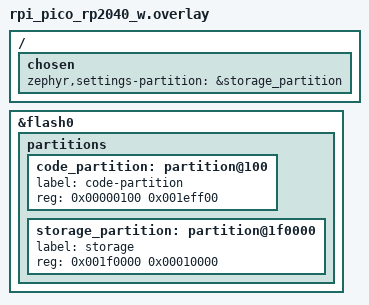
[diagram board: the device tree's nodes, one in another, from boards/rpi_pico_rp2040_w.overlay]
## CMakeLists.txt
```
cmake_minimum_required(VERSION 3.20.0)

# If you want to force the board from here (optional).
# You can also set BOARD in the CLion CMake profile instead.
set(BOARD rpi_pico/rp2040/w CACHE STRING "Zephyr board")

find_package(Zephyr REQUIRED HINTS $ENV{ZEPHYR_BASE})
project(slider)

# App sources
target_sources(app PRIVATE
        src/main.c
        src/wifi_scanner.c
        src/wifi_ap_provisioning.c
        src/http_server.c
        src/wifi_config_gui.c
        src/wifi_shell_commands.c
)

# If you keep headers in src/ (e.g., wifi_creds.h), this is optional because
# Zephyr already adds the app dir include path, but it's harmless and explicit.
target_include_directories(app PRIVATE
        ${CMAKE_CURRENT_SOURCE_DIR}/src
)
```

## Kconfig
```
# This file is the application Kconfig entry point. All application Kconfig
# options can be defined here or included via other application Kconfig files.
# You can browse these options using the west targets menuconfig (terminal) or
# guiconfig (GUI).

menu "Zephyr"
source "Kconfig.zephyr"
endmenu

module = SLIDER
module-str = SLIDER
source "subsys/logging/Kconfig.template.log_config"
```

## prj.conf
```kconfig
# ===============================
# Console + logging + shell
# ===============================
CONFIG_SERIAL=y
CONFIG_CONSOLE=y
CONFIG_UART_CONSOLE=y

CONFIG_LOG=y
CONFIG_LOG_MODE_DEFERRED=y
CONFIG_LOG_DEFAULT_LEVEL=3
CONFIG_LOG_BACKEND_UART=y

# Shell
CONFIG_SHELL=y
CONFIG_SHELL_BACKEND_SERIAL=y
CONFIG_SHELL_PROMPT_UART="slider:~$ "
CONFIG_REBOOT=y

# ===============================
# Flash + partitions
# ===============================
CONFIG_FLASH=y
CONFIG_FLASH_MAP=y

# ===============================
# Settings subsystem (ZMS backend)
# ===============================
CONFIG_SETTINGS=y
CONFIG_SETTINGS_ZMS=y
CONFIG_SETTINGS_RUNTIME=y
CONFIG_ZMS=y
CONFIG_MPU_ALLOW_FLASH_WRITE=y

# ===============================
# Networking + WiFi
# ===============================
CONFIG_NETWORKING=y
CONFIG_NET_IPV4=y
CONFIG_NET_DHCPV4=y
CONFIG_NET_DHCPV4_SERVER=y
CONFIG_NET_MGMT=y
CONFIG_NET_MGMT_EVENT=y

CONFIG_WIFI=y
CONFIG_NET_L2_WIFI_SHELL=y

# Random number generator (required for networking)
CONFIG_ENTROPY_GENERATOR=y
CONFIG_TEST_RANDOM_GENERATOR=y

# Stack sizes for networking and threads
CONFIG_MAIN_STACK_SIZE=8192
CONFIG_NET_TX_STACK_SIZE=4096
CONFIG_NET_RX_STACK_SIZE=4096
CONFIG_SYSTEM_WORKQUEUE_STACK_SIZE=4096

# Additional networking features
CONFIG_NET_SOCKETS=y
CONFIG_POSIX_API=y
CONFIG_NET_TCP=y

# HTTP server requirements
CONFIG_NET_BUF_DATA_SIZE=256
CONFIG_NET_PKT_RX_COUNT=16
CONFIG_NET_PKT_TX_COUNT=16
CONFIG_NET_BUF_RX_COUNT=32
CONFIG_NET_BUF_TX_COUNT=32
CONFIG_NET_MAX_CONTEXTS=10

# Increase heap for dynamic allocations
CONFIG_HEAP_MEM_POOL_SIZE=16384

# Additional shell features
CONFIG_SHELL_STACK_SIZE=4096
CONFIG_SHELL_ARGC_MAX=8
CONFIG_SHELL_CMD_BUFF_SIZE=256
```

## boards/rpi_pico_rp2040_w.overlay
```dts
/ {
	chosen {
		zephyr,settings-partition = &storage_partition;
	};
};

&flash0 {
	partitions {
		/* Shrink code partition to make room for storage */
		code_partition: partition@100 {
			label = "code-partition";
			reg = <0x00000100 0x001eff00>;  /* Code: 256B to 1.937MB */
		};

		/* Storage partition at the end */
		storage_partition: partition@1f0000 {
			label = "storage";
			reg = <0x001f0000 0x00010000>;  /* Storage: last 64KB */
		};
	};
};
```

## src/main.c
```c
/*
 * WiFi Configuration System for Raspberry Pi Pico W
 *
 * Demonstrates comprehensive WiFi management using Zephyr Settings API with ZMS backend.
 *
 * Features:
 * - Boot counter that increments on each reboot
 * - WiFi credential storage (SSID and password)
 * - Automatic WiFi connection on boot if credentials are stored
 * - WiFi network scanning
 * - AP provisioning mode with HTTP configuration interface
 * - GUI framework for display-based configuration
 * - Extended shell commands for management
 * - Persistent storage survives power cycles
 *
 * Shell Commands:
 *   wifi set_ssid <ssid>      - Store WiFi SSID
 *   wifi set_password <pass>  - Store WiFi password
 *   wifi connect              - Connect to WiFi using stored credentials
 *   wifi status               - Show WiFi connection status
 *   wifi_ext reset            - Clear stored WiFi credentials
 *   wifi_ext scan             - Scan for available networks
 *   wifi_ext provision        - Start AP provisioning mode
 *   demo show                 - Display current settings
 *   kernel reboot             - Reboot to test persistence
 */

#include <zephyr/kernel.h>
#include <zephyr/sys/printk.h>
#include <zephyr/settings/settings.h>
#include <zephyr/shell/shell.h>
#include <zephyr/devicetree.h>
#include <zephyr/storage/flash_map.h>
#include <zephyr/device.h>
#include <zephyr/net/net_if.h>
#include <zephyr/net/net_mgmt.h>
#include <zephyr/net/wifi_mgmt.h>
#include <zephyr/net/net_ip.h>
#include <string.h>

/* WiFi configuration modules */
#include "wifi_scanner.h"
#include "wifi_ap_provisioning.h"
#include "http_server.h"
#include "wifi_config_gui.h"
#include "wifi_shell_commands.h"

#define STORAGE_PARTITION_ID FIXED_PARTITION_ID(storage_partition)

/* Settings values */
static uint32_t boot_count = 0;

/* WiFi credentials */
#define WIFI_SSID_MAX 32
#define WIFI_PSK_MAX 64
static char wifi_ssid[WIFI_SSID_MAX + 1] = "";
static char wifi_psk[WIFI_PSK_MAX + 1] = "";
static bool wifi_credentials_set = false;

/* WiFi connection state */
static struct net_mgmt_event_callback wifi_cb;
static bool wifi_connected = false;
static K_SEM_DEFINE(wifi_connected_sem, 0, 1);

/* WiFi configuration system components */
static struct wifi_scanner scanner;
static struct wifi_ap_provisioning ap_prov;
static struct http_server http_srv;
static bool provisioning_mode = false;

/* Forward declarations */
static void provisioning_creds_received(const char *ssid,
                                         const char *password,
                                         void *user_data);
static void start_http_server(void);

/*
 * Settings handler: Set (called when loading from storage)
 */
static int demo_handle_set(const char *name, size_t len,
                           settings_read_cb read_cb, void *cb_arg)
{
    int rc;

    if (strcmp(name, "boot_count") == 0) {
        if (len != sizeof(boot_count)) {
            return -EINVAL;
        }
        rc = read_cb(cb_arg, &boot_count, sizeof(boot_count));
        if (rc >= 0) {
            printk("Loaded boot_count = %u\n", boot_count);
            return 0;
        }
        return rc;
    }

    if (strcmp(name, "wifi_ssid") == 0) {
        if (len > WIFI_SSID_MAX) {
            return -EINVAL;
        }
        rc = read_cb(cb_arg, wifi_ssid, len);
        if (rc >= 0) {
            wifi_ssid[len] = '\0';
            printk("Loaded WiFi SSID = '%s'\n", wifi_ssid);
            return 0;
        }
        return rc;
    }

    if (strcmp(name, "wifi_psk") == 0) {
        if (len > WIFI_PSK_MAX) {
            return -EINVAL;
        }
        rc = read_cb(cb_arg, wifi_psk, len);
        if (rc >= 0) {
            wifi_psk[len] = '\0';
            printk("Loaded WiFi password (***)\n");
            wifi_credentials_set = true;
            return 0;
        }
        return rc;
    }

    return -ENOENT;
}

/*
 * Settings handler: Commit (called after all settings loaded)
 */
static int demo_handle_commit(void)
{
    printk("Settings loaded successfully\n");
    return 0;
}

/*
 * Settings handler: Export (called by settings_save() to enumerate values)
 */
static int demo_handle_export(int (*cb)(const char *name,
                                        const void *value,
                                        size_t val_len))
{
    /* Export with full path including subtree prefix */
    (void)cb("demo/boot_count", &boot_count, sizeof(boot_count));

    if (strlen(wifi_ssid) > 0) {
        (void)cb("demo/wifi_ssid", wifi_ssid, strlen(wifi_ssid));
    }

    if (strlen(wifi_psk) > 0) {
        (void)cb("demo/wifi_psk", wifi_psk, strlen(wifi_psk));
    }

    return 0;
}

/* Register static handler for "demo" subtree */
SETTINGS_STATIC_HANDLER_DEFINE(demo_handler, "demo",
                               NULL,                 /* h_get */
                               demo_handle_set,      /* h_set */
                               demo_handle_commit,   /* h_commit */
                               demo_handle_export);  /* h_export */

/*
 * WiFi event handler
 */
static void wifi_mgmt_event_handler(struct net_mgmt_event_callback *cb,
                                    uint64_t mgmt_event, struct net_if *iface)
{
    const struct wifi_status *status = (const struct wifi_status *)cb->info;

    switch (mgmt_event) {
    case NET_EVENT_WIFI_CONNECT_RESULT:
        if (status->status == 0) {
            wifi_connected = true;
            printk("Connected\n");
        } else {
            printk("Connection failed (status: %d)\n", status->status);
        }
        k_sem_give(&wifi_connected_sem);
        break;
    case NET_EVENT_WIFI_DISCONNECT_RESULT:
        wifi_connected = false;
        printk("Disconnected\n");
        break;
    default:
        break;
    }
}

/*
 * Connect to WiFi using stored credentials
 */
static int wifi_connect_stored(void)
{
    struct net_if *iface = net_if_get_default();
    struct wifi_connect_req_params params = {0};

    if (!iface) {
        printk("ERROR: No network interface found\n");
        return -ENODEV;
    }

    if (strlen(wifi_ssid) == 0) {
        printk("ERROR: No WiFi SSID configured\n");
        return -EINVAL;
    }

    printk("Connecting to WiFi SSID: %s\n", wifi_ssid);

    params.ssid = wifi_ssid;
    params.ssid_length = strlen(wifi_ssid);
    params.psk = wifi_psk;
    params.psk_length = strlen(wifi_psk);
    params.channel = WIFI_CHANNEL_ANY;
    params.security = (strlen(wifi_psk) > 0) ? WIFI_SECURITY_TYPE_PSK : WIFI_SECURITY_TYPE_NONE;
    params.band = WIFI_FREQ_BAND_2_4_GHZ;
    params.mfp = WIFI_MFP_OPTIONAL;

    /* Reset semaphore before connecting */
    k_sem_reset(&wifi_connected_sem);

    /* Send connection request - this is asynchronous */
    net_mgmt(NET_REQUEST_WIFI_CONNECT, iface, &params, sizeof(params));

    /* Wait for connection result event */
    if (k_sem_take(&wifi_connected_sem, K_SECONDS(30)) != 0) {
        printk("Connection timeout\n");
        return -ETIMEDOUT;
    }

    return wifi_connected ? 0 : -ENOEXEC;
}

/*
 * Shell command: set WiFi SSID
 */
static int cmd_wifi_set_ssid(const struct shell *sh, size_t argc, char **argv)
{
    int rc;

    if (argc != 2) {
        shell_error(sh, "Usage: set_ssid <ssid>");
        return -EINVAL;
    }

    if (strlen(argv[1]) > WIFI_SSID_MAX) {
        shell_error(sh, "SSID too long (max %d)", WIFI_SSID_MAX);
        return -EINVAL;
    }

    strncpy(wifi_ssid, argv[1], WIFI_SSID_MAX);
    wifi_ssid[WIFI_SSID_MAX] = '\0';

    rc = settings_save();
    if (rc) {
        shell_error(sh, "Failed to save: %d", rc);
        return rc;
    }

    shell_print(sh, "WiFi SSID saved: '%s'", wifi_ssid);
    return 0;
}

/*
 * Shell command: set WiFi password
 */
static int cmd_wifi_set_password(const struct shell *sh, size_t argc, char **argv)
{
    int rc;

    if (argc != 2) {
        shell_error(sh, "Usage: set_password <password>");
        return -EINVAL;
    }

    if (strlen(argv[1]) > WIFI_PSK_MAX) {
        shell_error(sh, "Password too long (max %d)", WIFI_PSK_MAX);
        return -EINVAL;
    }

    strncpy(wifi_psk, argv[1], WIFI_PSK_MAX);
    wifi_psk[WIFI_PSK_MAX] = '\0';
    wifi_credentials_set = true;

    rc = settings_save();
    if (rc) {
        shell_error(sh, "Failed to save: %d", rc);
        return rc;
    }

    shell_print(sh, "WiFi password saved");
    return 0;
}

/*
 * Start HTTP configuration server
 */
static void start_http_server(void)
{
    int rc;

    /* Check if already running */
    if (http_srv.state == HTTP_SERVER_RUNNING) {
        printk("HTTP server already running\n");
        return;
    }

    /* Wait for DHCP to complete and get IP address */
    printk("Waiting for IP address...\n");
    k_msleep(3000);

    /* Start HTTP server for web configuration interface */
    printk("Starting HTTP configuration server...\n");

    /* Initialize WiFi scanner if not already done */
    if (scanner.state == WIFI_SCANNER_IDLE) {
        rc = wifi_scanner_init(&scanner);
        if (rc) {
            printk("Warning: WiFi scanner init failed: %d\n", rc);
        }
    }

    /* Initialize HTTP server */
    rc = http_server_init(&http_srv, &scanner);
    if (rc == 0) {
        rc = http_server_start(&http_srv, provisioning_creds_received, NULL);
        if (rc == 0) {
            struct net_if *iface = net_if_get_default();
            if (iface && iface->config.ip.ipv4 &&
                iface->config.ip.ipv4->unicast[0].ipv4.addr_state == NET_ADDR_PREFERRED) {
                struct in_addr *addr = &iface->config.ip.ipv4->unicast[0].ipv4.address.in_addr;
                printk("\n");
                printk("===========================================\n");
                printk("  WiFi Configuration Interface Ready\n");
                printk("===========================================\n");
                printk("  Open browser to: http://%d.%d.%d.%d\n",
                       addr->s4_addr[0], addr->s4_addr[1],
                       addr->s4_addr[2], addr->s4_addr[3]);
                printk("===========================================\n\n");
            } else {
                printk("HTTP server started (waiting for IP address)\n");
                printk("Use 'net iface' to check IP address\n");
            }
        } else {
            printk("Warning: Failed to start HTTP server: %d\n", rc);
        }
    } else {
        printk("Warning: Failed to init HTTP server: %d\n", rc);
    }
}

/*
 * Shell command: connect to WiFi
 */
static int cmd_wifi_connect(const struct shell *sh, size_t argc, char **argv)
{
    int rc = wifi_connect_stored();
    if (rc) {
        shell_error(sh, "WiFi connection failed: %d", rc);
        return rc;
    }

    shell_print(sh, "WiFi connected successfully");

    /* Start HTTP server after successful connection */
    start_http_server();

    return 0;
}

/*
 * Shell command: reset WiFi credentials
 */
static int cmd_wifi_reset(const struct shell *sh, size_t argc, char **argv)
{
    int rc;

    shell_print(sh, "Resetting WiFi credentials...");

    /* Clear in-memory variables */
    memset(wifi_ssid, 0, sizeof(wifi_ssid));
    memset(wifi_psk, 0, sizeof(wifi_psk));
    wifi_credentials_set = false;

    /* Delete from persistent storage */
    rc = settings_delete("demo/wifi_ssid");
    if (rc && rc != -ENOENT) {
        shell_error(sh, "Failed to delete SSID: %d", rc);
    }

    rc = settings_delete("demo/wifi_psk");
    if (rc && rc != -ENOENT) {
        shell_error(sh, "Failed to delete password: %d", rc);
    }

    /* Save to persist deletion */
    rc = settings_save();
    if (rc) {
        shell_error(sh, "Failed to save: %d", rc);
        return rc;
    }

    shell_print(sh, "WiFi credentials cleared successfully");
    shell_print(sh, "Device will enter provisioning mode on next boot");
    return 0;
}

/*
 * Shell command: show WiFi status
 */
static int cmd_wifi_status(const struct shell *sh, size_t argc, char **argv)
{
    shell_print(sh, "WiFi Status:");
    shell_print(sh, "  SSID: %s", strlen(wifi_ssid) > 0 ? wifi_ssid : "<not set>");
    shell_print(sh, "  Password: %s", strlen(wifi_psk) > 0 ? "***" : "<not set>");
    shell_print(sh, "  Connected: %s", wifi_connected ? "Yes" : "No");
    return 0;
}

/*
 * Shell command: show all settings
 */
static int cmd_show(const struct shell *sh, size_t argc, char **argv)
{
    shell_print(sh, "Settings:");
    shell_print(sh, "  Boot count: %u", boot_count);
    shell_print(sh, "  WiFi SSID: %s", strlen(wifi_ssid) > 0 ? wifi_ssid : "<not set>");
    shell_print(sh, "  WiFi Password: %s", strlen(wifi_psk) > 0 ? "***" : "<not set>");
    shell_print(sh, "  WiFi Connected: %s", wifi_connected ? "Yes" : "No");
    return 0;
}

/* Register WiFi shell commands */
SHELL_STATIC_SUBCMD_SET_CREATE(wifi_cmds,
    SHELL_CMD(set_ssid, NULL, "Set WiFi SSID", cmd_wifi_set_ssid),
    SHELL_CMD(set_password, NULL, "Set WiFi password", cmd_wifi_set_password),
    SHELL_CMD(connect, NULL, "Connect to WiFi", cmd_wifi_connect),
    SHELL_CMD(reset, NULL, "Clear WiFi credentials", cmd_wifi_reset),
    SHELL_CMD(status, NULL, "Show WiFi status", cmd_wifi_status),
    SHELL_SUBCMD_SET_END
);

SHELL_CMD_REGISTER(wifi, &wifi_cmds, "WiFi commands", NULL);

/* Register demo shell commands */
SHELL_STATIC_SUBCMD_SET_CREATE(demo_cmds,
    SHELL_CMD(show, NULL, "Show all settings", cmd_show),
    SHELL_SUBCMD_SET_END
);

SHELL_CMD_REGISTER(demo, &demo_cmds, "Settings demo commands", NULL);

/*
 * Provisioning credentials callback
 *
 * Called when user submits WiFi credentials via AP provisioning interface
 */
static void provisioning_creds_received(const char *ssid,
                                         const char *password,
                                         void *user_data)
{
	ARG_UNUSED(user_data);

	printk("\n=== New WiFi Credentials Received ===\n");
	printk("SSID: %s\n", ssid);
	printk("Password: ***\n");

	/* Store new credentials */
	if (strlen(ssid) <= WIFI_SSID_MAX) {
		strncpy(wifi_ssid, ssid, WIFI_SSID_MAX);
		wifi_ssid[WIFI_SSID_MAX] = '\0';
	}

	if (strlen(password) <= WIFI_PSK_MAX) {
		strncpy(wifi_psk, password, WIFI_PSK_MAX);
		wifi_psk[WIFI_PSK_MAX] = '\0';
		wifi_credentials_set = true;
	}

	/* Save to flash */
	int rc = settings_save();
	if (rc) {
		printk("Warning: Failed to save credentials: %d\n", rc);
	} else {
		printk("Credentials saved to flash\n");
	}

	/* Stop provisioning mode */
	printk("Stopping provisioning mode...\n");
	http_server_stop(&http_srv);
	wifi_ap_provisioning_stop(&ap_prov);
	provisioning_mode = false;

	/* Wait for AP to fully stop before attempting station mode */
	printk("Waiting for AP to shut down...\n");
	k_msleep(2000);

	/* Try to connect to new network */
	printk("Attempting to connect to new network...\n");
	wifi_connect_stored();
}

/*
 * Start AP provisioning mode
 *
 * Creates an access point and HTTP server for WiFi configuration
 */
static int start_provisioning_mode(void)
{
	int rc;

	if (provisioning_mode) {
		printk("Already in provisioning mode\n");
		return 0;
	}

	printk("\n=== Entering Provisioning Mode ===\n");

	/* Initialize WiFi scanner */
	rc = wifi_scanner_init(&scanner);
	if (rc) {
		printk("ERROR: WiFi scanner init failed: %d\n", rc);
		return rc;
	}

	/* Scan for networks to show in web interface */
	printk("Scanning for WiFi networks...\n");
	rc = wifi_scanner_scan(&scanner, 10000);
	if (rc) {
		printk("Warning: WiFi scan failed: %d\n", rc);
	} else {
		size_t count;
		wifi_scanner_get_results(&scanner, &count);
		printk("Found %zu networks\n", count);
	}

	/* Initialize HTTP server */
	rc = http_server_init(&http_srv, &scanner);
	if (rc) {
		printk("ERROR: HTTP server init failed: %d\n", rc);
		return rc;
	}

	/* Initialize AP provisioning */
	rc = wifi_ap_provisioning_init(&ap_prov, NULL);
	if (rc) {
		printk("ERROR: AP provisioning init failed: %d\n", rc);
		return rc;
	}

	/* Note: AP mode support on Pico W is limited in Zephyr.
	 * For now, provisioning via serial shell is the primary method.
	 * Future: Add BLE provisioning or use external AP hardware.
	 */

	/* Start AP - may not be fully supported on CYW43439 */
	rc = wifi_ap_provisioning_start(&ap_prov, provisioning_creds_received, NULL);
	if (rc) {
		printk("WARNING: AP mode not available: %d\n", rc);
		printk("Use shell commands for WiFi configuration:\n");
		printk("  wifi set_ssid <ssid>\n");
		printk("  wifi set_password <pass>\n");
		printk("  wifi connect\n");
		/* Don't fail - allow shell configuration */
		provisioning_mode = false;
		return 0;
	}

	/* Start HTTP server */
	rc = http_server_start(&http_srv, provisioning_creds_received, NULL);
	if (rc) {
		printk("ERROR: Failed to start HTTP server: %d\n", rc);
		wifi_ap_provisioning_stop(&ap_prov);
		return rc;
	}

	provisioning_mode = true;

	printk("\n");
	printk("===========================================\n");
	printk("  WiFi Provisioning Mode Active\n");
	printk("===========================================\n");
	printk("1. Connect to WiFi network: %s\n", WIFI_AP_DEFAULT_SSID);
	printk("2. Open browser to: http://%s\n", WIFI_AP_DEFAULT_IP);
	printk("3. Select your WiFi network and enter password\n");
	printk("===========================================\n\n");

	return 0;
}

/*
 * Main application
 */
int main(void)
{
    int rc;
    const struct flash_area *fa;
    const struct device *flash_dev;

    printk("\n=== Settings Demo ===\n");
    printk("Board: Raspberry Pi Pico W\n\n");

    /* Verify flash device is ready */
    rc = flash_area_open(STORAGE_PARTITION_ID, &fa);
    if (rc) {
        printk("ERROR: Failed to open storage partition: %d\n", rc);
        return rc;
    }

    flash_dev = fa->fa_dev;
    if (!device_is_ready(flash_dev)) {
        printk("ERROR: Flash device not ready\n");
        flash_area_close(fa);
        return -ENODEV;
    }

    printk("Flash storage ready (offset=0x%lx size=0x%lx)\n",
           (unsigned long)fa->fa_off, (unsigned long)fa->fa_size);
    flash_area_close(fa);

    /* Initialize settings subsystem */
    rc = settings_subsys_init();
    if (rc) {
        printk("ERROR: Settings initialization failed: %d\n", rc);
        return rc;
    }

    /* Load existing settings from flash */
    rc = settings_load();
    if (rc) {
        printk("Warning: Settings load returned %d\n", rc);
    }

    /* Increment and save boot counter */
    boot_count++;
    printk("\nBoot count: %u\n", boot_count);

    rc = settings_save();
    if (rc) {
        printk("Warning: Failed to save boot count: %d\n", rc);
    }

    /* Initialize WiFi management callbacks */
    net_mgmt_init_event_callback(&wifi_cb, wifi_mgmt_event_handler,
                                 NET_EVENT_WIFI_CONNECT_RESULT |
                                 NET_EVENT_WIFI_DISCONNECT_RESULT);
    net_mgmt_add_event_callback(&wifi_cb);

    /* Initialize extended WiFi shell commands */
    wifi_shell_commands_init(&scanner, &ap_prov);

    /* Auto-connect to WiFi if credentials are stored */
    if (strlen(wifi_ssid) > 0 && wifi_credentials_set) {
        printk("\nAuto-connecting to WiFi...\n");

        /* Wait for WiFi subsystem to be fully ready */
        k_msleep(2000);

        rc = wifi_connect_stored();
        if (rc == 0) {
            printk("Auto-connect successful\n");
            start_http_server();
        } else {
            printk("Auto-connect failed (use 'wifi connect' to retry)\n");
        }
    } else {
        printk("\nNo WiFi credentials stored.\n");
        printk("Entering AP provisioning mode...\n");

        /* Start provisioning mode if no credentials */
        rc = start_provisioning_mode();
        if (rc) {
            printk("ERROR: Failed to start provisioning mode: %d\n", rc);
            printk("Use shell commands to configure WiFi manually\n");
        }
    }

    /* Display available commands */
    printk("\nShell commands:\n");
    printk("  wifi set_ssid <ssid>      - Store WiFi SSID\n");
    printk("  wifi set_password <pass>  - Store WiFi password\n");
    printk("  wifi connect              - Connect to WiFi\n");
    printk("  wifi status               - Show WiFi status\n");
    printk("  wifi_ext reset            - Clear WiFi credentials\n");
    printk("  wifi_ext scan             - Scan for networks\n");
    printk("  wifi_ext provision        - Start provisioning mode\n");
    printk("  demo show                 - Show all settings\n");
    printk("  kernel reboot             - Test persistence\n\n");

    /* Main loop */
    while (1) {
        k_sleep(K_SECONDS(10));
    }

    return 0;
}
```

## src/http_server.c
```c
/**
 * @file http_server.c
 * @brief Simple HTTP server implementation for WiFi provisioning
 */

#include "http_server.h"
#include <zephyr/net/socket.h>
#include <zephyr/logging/log.h>
#include <string.h>
#include <stdio.h>

LOG_MODULE_REGISTER(http_server, LOG_LEVEL_INF);

/* HTTP server thread stack */
#define HTTP_SERVER_STACK_SIZE 4096
#define HTTP_SERVER_PRIORITY 5

K_THREAD_STACK_DEFINE(http_server_stack, HTTP_SERVER_STACK_SIZE);

/* HTML template for configuration page */
static const char html_header[] =
	"HTTP/1.1 200 OK\r\n"
	"Content-Type: text/html\r\n"
	"Connection: close\r\n\r\n";

static const char html_page_start[] =
	"<!DOCTYPE html><html><head>"
	"<meta name='viewport' content='width=device-width,initial-scale=1'>"
	"<title>WiFi Setup</title>"
	"<style>"
	"body{font-family:Arial,sans-serif;margin:20px;background:#f0f0f0;}"
	"h1{color:#333;}"
	".container{background:white;padding:20px;border-radius:8px;max-width:600px;margin:0 auto;}"
	".network{padding:10px;margin:5px 0;border:1px solid #ddd;border-radius:4px;cursor:pointer;}"
	".network:hover{background:#e8f4f8;}"
	".signal{float:right;color:#666;}"
	"input[type=text],input[type=password]{width:100%;padding:10px;margin:8px 0;border:1px solid #ddd;border-radius:4px;box-sizing:border-box;}"
	"button{background:#4CAF50;color:white;padding:12px 20px;border:none;border-radius:4px;cursor:pointer;width:100%;font-size:16px;}"
	"button:hover{background:#45a049;}"
	".security{color:#666;font-size:0.9em;}"
	"</style></head><body>"
	"<div class='container'>"
	"<h1>WiFi Configuration</h1>"
	"<p>Select a network or enter credentials manually:</p>";

static const char html_form[] =
	"<form method='POST' action='/connect'>"
	"<label>SSID:</label><input type='text' id='ssid' name='ssid' required>"
	"<label>Password:</label><input type='password' name='password'>"
	"<button type='submit'>Connect</button>"
	"</form>";

static const char html_page_end[] =
	"</div>"
	"<script>"
	"function selectNetwork(ssid){document.getElementById('ssid').value=ssid;}"
	"</script>"
	"</body></html>";

static const char html_success[] =
	"HTTP/1.1 200 OK\r\n"
	"Content-Type: text/html\r\n"
	"Connection: close\r\n\r\n"
	"<!DOCTYPE html><html><head><title>Success</title></head><body>"
	"<h1>WiFi Configuration Saved</h1>"
	"<p>The device will now attempt to connect to the specified network.</p>"
	"<p>This setup page will close shortly.</p>"
	"</body></html>";

/**
 * @brief Parse HTTP POST data for credentials
 *
 * @param data POST data string
 * @param ssid Output buffer for SSID
 * @param password Output buffer for password
 * @return 0 on success, -1 on failure
 */
static int parse_post_data(const char *data, char *ssid, char *password)
{
	const char *ssid_start, *ssid_end;
	const char *pass_start, *pass_end;

	/* Find SSID */
	ssid_start = strstr(data, "ssid=");
	if (!ssid_start) {
		return -1;
	}
	ssid_start += 5;  /* Skip "ssid=" */

	ssid_end = strchr(ssid_start, '&');
	if (!ssid_end) {
		ssid_end = ssid_start + strlen(ssid_start);
	}

	size_t ssid_len = ssid_end - ssid_start;
	if (ssid_len > 32) {
		ssid_len = 32;
	}
	strncpy(ssid, ssid_start, ssid_len);
	ssid[ssid_len] = '\0';

	/* URL decode SSID (replace + with space, handle %XX) */
	for (size_t i = 0; ssid[i]; i++) {
		if (ssid[i] == '+') {
			ssid[i] = ' ';
		}
	}

	/* Find password */
	pass_start = strstr(data, "password=");
	if (pass_start) {
		pass_start += 9;  /* Skip "password=" */
		pass_end = strchr(pass_start, '&');
		if (!pass_end) {
			pass_end = pass_start + strlen(pass_start);
		}

		size_t pass_len = pass_end - pass_start;
		if (pass_len > 64) {
			pass_len = 64;
		}
		strncpy(password, pass_start, pass_len);
		password[pass_len] = '\0';

		/* URL decode password */
		for (size_t i = 0; password[i]; i++) {
			if (password[i] == '+') {
				password[i] = ' ';
			}
		}
	} else {
		password[0] = '\0';
	}

	return 0;
}

/**
 * @brief Handle HTTP client connection
 *
 * @param server HTTP server context
 * @param client_sock Client socket
 */
static void handle_client(struct http_server *server, int client_sock)
{
	char buffer[1024];
	int ret;

	/* Receive HTTP request */
	ret = recv(client_sock, buffer, sizeof(buffer) - 1, 0);
	if (ret <= 0) {
		close(client_sock);
		return;
	}
	buffer[ret] = '\0';

	LOG_DBG("HTTP request received: %d bytes", ret);

	/* Check if POST request with credentials */
	if (strncmp(buffer, "POST /connect", 13) == 0) {
		char ssid[33] = {0};
		char password[65] = {0};

		/* Find POST data (after \r\n\r\n) */
		const char *post_data = strstr(buffer, "\r\n\r\n");
		if (post_data && parse_post_data(post_data + 4, ssid, password) == 0) {
			LOG_INF("Credentials received: SSID=%s", ssid);

			/* Send success response */
			send(client_sock, html_success, strlen(html_success), 0);

			/* Call credentials callback */
			if (server->creds_cb) {
				server->creds_cb(ssid, password, server->cb_user_data);
			}
		}
	} else {
		/* Send configuration page */
		send(client_sock, html_header, strlen(html_header), 0);
		send(client_sock, html_page_start, strlen(html_page_start), 0);

		/* Add scan results if available */
		if (server->scanner) {
			size_t count;
			const struct wifi_scan_result *results =
				wifi_scanner_get_results(server->scanner, &count);

			if (results && count > 0) {
				char network_html[256];

				send(client_sock, "<h2>Available Networks:</h2>", 28, 0);

				for (size_t i = 0; i < count; i++) {
					int signal_bars = (results[i].rssi + 100) / 15;
					if (signal_bars < 0) signal_bars = 0;
					if (signal_bars > 4) signal_bars = 4;

					snprintf(network_html, sizeof(network_html),
					         "<div class='network' onclick='selectNetwork(\"%s\")'>"
					         "%s <span class='signal'>Signal: %d dBm</span><br>"
					         "<span class='security'>%s</span></div>",
					         results[i].ssid, results[i].ssid, results[i].rssi,
					         wifi_scanner_security_to_string(results[i].security));

					send(client_sock, network_html, strlen(network_html), 0);
				}
			}
		}

		/* Send form and end of page */
		send(client_sock, "<h2>Enter Credentials:</h2>", 28, 0);
		send(client_sock, html_form, strlen(html_form), 0);
		send(client_sock, html_page_end, strlen(html_page_end), 0);
	}

	close(client_sock);
}

/**
 * @brief HTTP server thread function
 *
 * @param arg1 Pointer to http_server context
 * @param arg2 Unused
 * @param arg3 Unused
 */
static void http_server_thread(void *arg1, void *arg2, void *arg3)
{
	struct http_server *server = (struct http_server *)arg1;
	struct sockaddr_in addr;
	int ret;

	ARG_UNUSED(arg2);
	ARG_UNUSED(arg3);

	LOG_INF("HTTP server thread started");

	/* Create listening socket */
	server->listen_sock = socket(AF_INET, SOCK_STREAM, IPPROTO_TCP);
	if (server->listen_sock < 0) {
		LOG_ERR("Failed to create socket: %d", errno);
		printk("ERROR: HTTP server failed to create socket: %d\n", errno);
		server->state = HTTP_SERVER_FAILED;
		return;
	}
	printk("HTTP server: socket created (fd=%d)\n", server->listen_sock);

	/* Bind to port */
	addr.sin_family = AF_INET;
	addr.sin_port = htons(HTTP_SERVER_PORT);
	addr.sin_addr.s_addr = INADDR_ANY;

	ret = bind(server->listen_sock, (struct sockaddr *)&addr, sizeof(addr));
	if (ret < 0) {
		LOG_ERR("Failed to bind socket: %d", errno);
		printk("ERROR: HTTP server failed to bind to port %d: %d\n", HTTP_SERVER_PORT, errno);
		close(server->listen_sock);
		server->state = HTTP_SERVER_FAILED;
		return;
	}
	printk("HTTP server: bound to port %d\n", HTTP_SERVER_PORT);

	/* Listen for connections */
	ret = listen(server->listen_sock, HTTP_SERVER_MAX_CONNECTIONS);
	if (ret < 0) {
		LOG_ERR("Failed to listen: %d", errno);
		printk("ERROR: HTTP server failed to listen: %d\n", errno);
		close(server->listen_sock);
		server->state = HTTP_SERVER_FAILED;
		return;
	}

	server->state = HTTP_SERVER_RUNNING;
	LOG_INF("HTTP server listening on port %d", HTTP_SERVER_PORT);
	printk("HTTP server: listening on port %d (ready for connections)\n", HTTP_SERVER_PORT);

	/* Accept and handle connections */
	while (server->running) {
		struct sockaddr_in client_addr;
		socklen_t client_addr_len = sizeof(client_addr);

		int client_sock = accept(server->listen_sock,
		                          (struct sockaddr *)&client_addr,
		                          &client_addr_len);

		if (client_sock < 0) {
			if (server->running) {
				LOG_ERR("Accept failed: %d", errno);
				printk("HTTP server: accept failed: %d\n", errno);
			}
			break;
		}

		LOG_DBG("Client connected");
		printk("HTTP server: client connected from %d.%d.%d.%d\n",
		       ((uint8_t *)&client_addr.sin_addr.s_addr)[0],
		       ((uint8_t *)&client_addr.sin_addr.s_addr)[1],
		       ((uint8_t *)&client_addr.sin_addr.s_addr)[2],
		       ((uint8_t *)&client_addr.sin_addr.s_addr)[3]);
		handle_client(server, client_sock);
	}

	close(server->listen_sock);
	server->state = HTTP_SERVER_STOPPED;
	LOG_INF("HTTP server thread stopped");
}

int http_server_init(struct http_server *server, struct wifi_scanner *scanner)
{
	if (!server) {
		return -EINVAL;
	}

	memset(server, 0, sizeof(struct http_server));
	server->state = HTTP_SERVER_STOPPED;
	server->scanner = scanner;

	LOG_INF("HTTP server initialized");
	return 0;
}

int http_server_start(struct http_server *server,
                       http_server_creds_cb_t creds_cb,
                       void *user_data)
{
	if (!server) {
		return -EINVAL;
	}

	if (server->state == HTTP_SERVER_RUNNING) {
		LOG_WRN("HTTP server already running");
		return -EALREADY;
	}

	server->creds_cb = creds_cb;
	server->cb_user_data = user_data;
	server->running = true;
	server->state = HTTP_SERVER_STARTING;

	/* Create server thread */
	server->server_tid = k_thread_create(
		&server->server_thread,
		http_server_stack,
		HTTP_SERVER_STACK_SIZE,
		http_server_thread,
		server, NULL, NULL,
		HTTP_SERVER_PRIORITY,
		0, K_NO_WAIT);

	if (!server->server_tid) {
		LOG_ERR("Failed to create server thread");
		server->state = HTTP_SERVER_FAILED;
		return -ENOMEM;
	}

	k_thread_name_set(&server->server_thread, "http_server");

	LOG_INF("HTTP server starting...");
	return 0;
}

int http_server_stop(struct http_server *server)
{
	if (!server) {
		return -EINVAL;
	}

	if (server->state != HTTP_SERVER_RUNNING) {
		return -EALREADY;
	}

	LOG_INF("Stopping HTTP server...");

	server->running = false;

	/* Close socket to unblock accept() */
	if (server->listen_sock >= 0) {
		close(server->listen_sock);
	}

	/* Wait for thread to finish */
	k_thread_join(&server->server_thread, K_SECONDS(5));

	return 0;
}

enum http_server_state http_server_get_state(struct http_server *server)
{
	if (!server) {
		return HTTP_SERVER_STOPPED;
	}

	return server->state;
}
```

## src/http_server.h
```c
/**
 * @file http_server.h
 * @brief Simple HTTP server for WiFi provisioning
 *
 * This module provides a lightweight HTTP server that serves a
 * web-based configuration interface for WiFi credential setup.
 */

#pragma once

#include <zephyr/kernel.h>
#include "wifi_scanner.h"

#ifdef __cplusplus
extern "C" {
#endif

/** HTTP server port */
#define HTTP_SERVER_PORT 80

/** Maximum number of concurrent connections */
#define HTTP_SERVER_MAX_CONNECTIONS 2

/**
 * @brief HTTP server state
 */
enum http_server_state {
	HTTP_SERVER_STOPPED,    /**< Server not running */
	HTTP_SERVER_STARTING,   /**< Server starting */
	HTTP_SERVER_RUNNING,    /**< Server running */
	HTTP_SERVER_FAILED      /**< Server failed */
};

/**
 * @brief Credentials submission callback
 *
 * Called when user submits WiFi credentials via web interface
 *
 * @param ssid Selected WiFi SSID
 * @param password WiFi password
 * @param user_data User data pointer
 */
typedef void (*http_server_creds_cb_t)(const char *ssid,
                                        const char *password,
                                        void *user_data);

/**
 * @brief HTTP server context
 */
struct http_server {
	enum http_server_state state;
	int listen_sock;
	struct k_thread server_thread;
	k_tid_t server_tid;
	http_server_creds_cb_t creds_cb;
	void *cb_user_data;
	struct wifi_scanner *scanner;  /**< Reference to WiFi scanner */
	bool running;
};

/**
 * @brief Initialize the HTTP server
 *
 * @param server Pointer to HTTP server context
 * @param scanner Pointer to WiFi scanner (for network list)
 * @return 0 on success, negative errno on failure
 */
int http_server_init(struct http_server *server, struct wifi_scanner *scanner);

/**
 * @brief Start the HTTP server
 *
 * Starts listening for HTTP connections and serves the configuration interface
 *
 * @param server Pointer to HTTP server context
 * @param creds_cb Callback for credential submissions
 * @param user_data User data passed to callback
 * @return 0 on success, negative errno on failure
 */
int http_server_start(struct http_server *server,
                       http_server_creds_cb_t creds_cb,
                       void *user_data);

/**
 * @brief Stop the HTTP server
 *
 * @param server Pointer to HTTP server context
 * @return 0 on success, negative errno on failure
 */
int http_server_stop(struct http_server *server);

/**
 * @brief Get server state
 *
 * @param server Pointer to HTTP server context
 * @return Current server state
 */
enum http_server_state http_server_get_state(struct http_server *server);

#ifdef __cplusplus
}
#endif
```

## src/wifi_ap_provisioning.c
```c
/**
 * @file wifi_ap_provisioning.c
 * @brief WiFi Access Point provisioning implementation
 */

#include "wifi_ap_provisioning.h"
#include <zephyr/net/net_if.h>
#include <zephyr/net/net_mgmt.h>
#include <zephyr/net/wifi_mgmt.h>
#include <zephyr/net/net_ip.h>
#include <zephyr/net/dhcpv4_server.h>
#include <zephyr/logging/log.h>
#include <string.h>
#include <arpa/inet.h>

LOG_MODULE_REGISTER(wifi_ap, LOG_LEVEL_INF);

/* Static instance for callback access */
static struct wifi_ap_provisioning *g_ap_instance = NULL;
static wifi_ap_creds_received_cb_t g_creds_callback = NULL;
static void *g_callback_user_data = NULL;

/**
 * @brief WiFi AP event handler
 *
 * Handles AP enable/disable events
 */
static void wifi_ap_event_handler(struct net_mgmt_event_callback *cb,
                                   uint64_t mgmt_event,
                                   struct net_if *iface)
{
	struct wifi_ap_provisioning *ap = g_ap_instance;

	if (!ap) {
		return;
	}

	switch (mgmt_event) {
	case NET_EVENT_WIFI_AP_ENABLE_RESULT:
	{
		const struct wifi_status *status = (const struct wifi_status *)cb->info;
		if (status && status->status == 0) {
			ap->state = WIFI_AP_ACTIVE;
			LOG_INF("WiFi AP enabled successfully");
		} else {
			ap->state = WIFI_AP_FAILED;
			LOG_ERR("WiFi AP enable failed: %d", status ? status->status : -1);
		}
		break;
	}
	case NET_EVENT_WIFI_AP_DISABLE_RESULT:
	{
		ap->state = WIFI_AP_IDLE;
		LOG_INF("WiFi AP disabled");
		break;
	}
	default:
		break;
	}
}

int wifi_ap_provisioning_init(struct wifi_ap_provisioning *ap,
                               const struct wifi_ap_config *config)
{
	if (!ap) {
		return -EINVAL;
	}

	/* Initialize context */
	memset(ap, 0, sizeof(struct wifi_ap_provisioning));
	ap->state = WIFI_AP_IDLE;

	/* Set configuration (use defaults if not provided) */
	if (config) {
		memcpy(&ap->config, config, sizeof(struct wifi_ap_config));
	} else {
		/* Use default configuration */
		strncpy(ap->config.ssid, WIFI_AP_DEFAULT_SSID, sizeof(ap->config.ssid) - 1);
		strncpy(ap->config.password, WIFI_AP_DEFAULT_PASSWORD, sizeof(ap->config.password) - 1);
		ap->config.channel = WIFI_AP_DEFAULT_CHANNEL;
		strncpy(ap->config.ip_addr, WIFI_AP_DEFAULT_IP, sizeof(ap->config.ip_addr) - 1);
	}

	/* Store global instance for callbacks */
	g_ap_instance = ap;

	/* Register AP event callbacks */
	net_mgmt_init_event_callback(&ap->ap_cb,
	                             wifi_ap_event_handler,
	                             NET_EVENT_WIFI_AP_ENABLE_RESULT |
	                             NET_EVENT_WIFI_AP_DISABLE_RESULT);
	net_mgmt_add_event_callback(&ap->ap_cb);

	LOG_INF("WiFi AP provisioning initialized (SSID: %s)", ap->config.ssid);
	return 0;
}

int wifi_ap_provisioning_start(struct wifi_ap_provisioning *ap,
                                wifi_ap_creds_received_cb_t creds_cb,
                                void *user_data)
{
	struct net_if *iface;
	struct wifi_connect_req_params ap_params = {0};
	int ret;

	if (!ap) {
		return -EINVAL;
	}

	if (ap->state == WIFI_AP_ACTIVE || ap->state == WIFI_AP_STARTING) {
		LOG_WRN("AP already active or starting");
		return -EALREADY;
	}

	/* Store callback */
	g_creds_callback = creds_cb;
	g_callback_user_data = user_data;

	/* Get network interface */
	iface = net_if_get_default();
	if (!iface) {
		LOG_ERR("No default network interface");
		return -ENODEV;
	}

	/* Configure AP parameters */
	ap_params.ssid = ap->config.ssid;
	ap_params.ssid_length = strlen(ap->config.ssid);
	ap_params.channel = ap->config.channel;
	ap_params.band = WIFI_FREQ_BAND_2_4_GHZ;

	/* Set security based on password */
	if (strlen(ap->config.password) > 0) {
		ap_params.security = WIFI_SECURITY_TYPE_PSK;
		ap_params.psk = ap->config.password;
		ap_params.psk_length = strlen(ap->config.password);
	} else {
		ap_params.security = WIFI_SECURITY_TYPE_NONE;
	}

	ap->state = WIFI_AP_STARTING;

	LOG_INF("Starting WiFi AP (SSID: %s, Channel: %u, Security: %s)",
	        ap_params.ssid, ap_params.channel,
	        ap_params.security == WIFI_SECURITY_TYPE_NONE ? "Open" : "WPA2-PSK");

	/* Enable AP mode */
	ret = net_mgmt(NET_REQUEST_WIFI_AP_ENABLE, iface, &ap_params, sizeof(ap_params));
	if (ret) {
		LOG_ERR("Failed to start WiFi AP: %d", ret);
		ap->state = WIFI_AP_FAILED;
		return ret;
	}

	/* Configure static IP address for AP interface */
	struct in_addr addr, netmask;
	struct net_if_addr *ifaddr;

	/* Set IP address: 192.168.4.1 */
	if (net_addr_pton(AF_INET, WIFI_AP_DEFAULT_IP, &addr) < 0) {
		LOG_ERR("Failed to parse AP IP address");
	} else {
		ifaddr = net_if_ipv4_addr_add(iface, &addr, NET_ADDR_MANUAL, 0);
		if (ifaddr) {
			LOG_INF("AP IP address set to %s", WIFI_AP_DEFAULT_IP);
		} else {
			LOG_ERR("Failed to add AP IP address");
		}
	}

	/* Set netmask: 255.255.255.0 */
	if (net_addr_pton(AF_INET, "255.255.255.0", &netmask) < 0) {
		LOG_ERR("Failed to parse netmask");
	} else {
		net_if_ipv4_set_netmask_by_addr(iface, &addr, &netmask);
	}

	/* Start DHCP server for clients */
	struct in_addr pool_start;
	printk("Attempting to start DHCP server...\n");

	/* Manually set the pool start address: 192.168.4.10 */
	pool_start.s_addr = htonl(0xC0A80A0A); /* 192.168.4.10 in network byte order */

	ret = net_dhcpv4_server_start(iface, &pool_start);
	if (ret == 0) {
		LOG_INF("DHCP server started (pool: 192.168.4.10-192.168.4.254)");
		printk("DHCP server started successfully (pool: 192.168.4.10-254)\n");
	} else {
		LOG_ERR("Failed to start DHCP server: error %d", ret);
		printk("ERROR: DHCP server failed to start: %d\n", ret);
		printk("Clients will need manual IP configuration (192.168.4.x/24)\n");
	}

	/* Note: The actual state will be updated by the event handler */

	return 0;
}

int wifi_ap_provisioning_stop(struct wifi_ap_provisioning *ap)
{
	struct net_if *iface;
	int ret;

	if (!ap) {
		return -EINVAL;
	}

	if (ap->state != WIFI_AP_ACTIVE) {
		LOG_WRN("AP not active");
		return -EALREADY;
	}

	/* Get network interface */
	iface = net_if_get_default();
	if (!iface) {
		LOG_ERR("No default network interface");
		return -ENODEV;
	}

	LOG_INF("Stopping WiFi AP");

	/* Disable AP mode */
	ret = net_mgmt(NET_REQUEST_WIFI_AP_DISABLE, iface, NULL, 0);
	if (ret) {
		LOG_ERR("Failed to stop WiFi AP: %d", ret);
		return ret;
	}

	/* TODO: Stop HTTP server */

	return 0;
}

enum wifi_ap_state wifi_ap_provisioning_get_state(struct wifi_ap_provisioning *ap)
{
	if (!ap) {
		return WIFI_AP_IDLE;
	}

	return ap->state;
}

bool wifi_ap_provisioning_has_credentials(struct wifi_ap_provisioning *ap)
{
	if (!ap) {
		return false;
	}

	return ap->credentials_received;
}

/**
 * @brief Process received credentials (called by HTTP server)
 *
 * This function would be called by the HTTP server when credentials
 * are submitted via the web interface.
 *
 * @param ssid New WiFi SSID
 * @param password New WiFi password
 */
void wifi_ap_provisioning_set_credentials(const char *ssid, const char *password)
{
	struct wifi_ap_provisioning *ap = g_ap_instance;

	if (!ap || !ssid) {
		return;
	}

	/* Store credentials */
	strncpy(ap->new_ssid, ssid, sizeof(ap->new_ssid) - 1);
	ap->new_ssid[sizeof(ap->new_ssid) - 1] = '\0';

	if (password) {
		strncpy(ap->new_password, password, sizeof(ap->new_password) - 1);
		ap->new_password[sizeof(ap->new_password) - 1] = '\0';
	} else {
		ap->new_password[0] = '\0';
	}

	ap->credentials_received = true;

	LOG_INF("Credentials received: SSID=%s", ap->new_ssid);

	/* Call user callback if registered */
	if (g_creds_callback) {
		g_creds_callback(ap->new_ssid, ap->new_password, g_callback_user_data);
	}
}
```

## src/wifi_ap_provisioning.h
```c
/**
 * @file wifi_ap_provisioning.h
 * @brief WiFi Access Point provisioning module
 *
 * This module creates a SoftAP (access point) that allows users to
 * configure WiFi credentials via a web interface when no stored
 * credentials are available.
 */

#pragma once

#include <zephyr/kernel.h>
#include <zephyr/net/net_mgmt.h>
#include <stdbool.h>

#ifdef __cplusplus
extern "C" {
#endif

/** Default AP SSID */
#define WIFI_AP_DEFAULT_SSID "PicoW-Setup"

/** Default AP password (empty = open network) */
#define WIFI_AP_DEFAULT_PASSWORD ""

/** Default AP channel */
#define WIFI_AP_DEFAULT_CHANNEL 6

/** Default AP IP address */
#define WIFI_AP_DEFAULT_IP "192.168.4.1"

/**
 * @brief WiFi AP provisioning state
 */
enum wifi_ap_state {
	WIFI_AP_IDLE,           /**< AP not started */
	WIFI_AP_STARTING,       /**< AP starting */
	WIFI_AP_ACTIVE,         /**< AP active and ready */
	WIFI_AP_FAILED          /**< AP failed to start */
};

/**
 * @brief WiFi AP configuration
 */
struct wifi_ap_config {
	char ssid[33];          /**< AP SSID */
	char password[65];      /**< AP password (empty for open) */
	uint8_t channel;        /**< WiFi channel */
	char ip_addr[16];       /**< AP IP address */
};

/**
 * @brief WiFi AP provisioning context
 */
struct wifi_ap_provisioning {
	struct wifi_ap_config config;
	enum wifi_ap_state state;
	struct net_mgmt_event_callback ap_cb;
	bool credentials_received;
	char new_ssid[33];      /**< New credentials from user */
	char new_password[65];  /**< New password from user */
};

/**
 * @brief Credentials received callback type
 *
 * Called when new WiFi credentials are received via the provisioning interface
 *
 * @param ssid New WiFi SSID
 * @param password New WiFi password
 * @param user_data User data pointer
 */
typedef void (*wifi_ap_creds_received_cb_t)(const char *ssid,
                                             const char *password,
                                             void *user_data);

/**
 * @brief Initialize the WiFi AP provisioning module
 *
 * @param ap Pointer to AP provisioning context
 * @param config AP configuration (NULL = use defaults)
 * @return 0 on success, negative errno on failure
 */
int wifi_ap_provisioning_init(struct wifi_ap_provisioning *ap,
                               const struct wifi_ap_config *config);

/**
 * @brief Start the WiFi access point
 *
 * Creates a SoftAP and starts the HTTP configuration server
 *
 * @param ap Pointer to AP provisioning context
 * @param creds_cb Callback for when credentials are received
 * @param user_data User data passed to callback
 * @return 0 on success, negative errno on failure
 */
int wifi_ap_provisioning_start(struct wifi_ap_provisioning *ap,
                                wifi_ap_creds_received_cb_t creds_cb,
                                void *user_data);

/**
 * @brief Stop the WiFi access point
 *
 * Stops the SoftAP and HTTP server
 *
 * @param ap Pointer to AP provisioning context
 * @return 0 on success, negative errno on failure
 */
int wifi_ap_provisioning_stop(struct wifi_ap_provisioning *ap);

/**
 * @brief Get AP provisioning state
 *
 * @param ap Pointer to AP provisioning context
 * @return Current AP state
 */
enum wifi_ap_state wifi_ap_provisioning_get_state(struct wifi_ap_provisioning *ap);

/**
 * @brief Check if credentials have been received
 *
 * @param ap Pointer to AP provisioning context
 * @return true if credentials received, false otherwise
 */
bool wifi_ap_provisioning_has_credentials(struct wifi_ap_provisioning *ap);

#ifdef __cplusplus
}
#endif
```

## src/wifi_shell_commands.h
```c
/**
 * @file wifi_shell_commands.h
 * @brief Extended WiFi shell commands
 *
 * This module provides additional shell commands for WiFi management,
 * including credential reset, network scanning, and provisioning control.
 */

#pragma once

#include <zephyr/kernel.h>
#include "wifi_scanner.h"
#include "wifi_ap_provisioning.h"

#ifdef __cplusplus
extern "C" {
#endif

/**
 * @brief Initialize WiFi shell commands
 *
 * Registers extended WiFi commands with the shell subsystem
 *
 * @param scanner Pointer to WiFi scanner context (optional, can be NULL)
 * @param ap_prov Pointer to AP provisioning context (optional, can be NULL)
 * @return 0 on success, negative errno on failure
 */
int wifi_shell_commands_init(struct wifi_scanner *scanner,
                              struct wifi_ap_provisioning *ap_prov);

#ifdef __cplusplus
}
#endif
```
